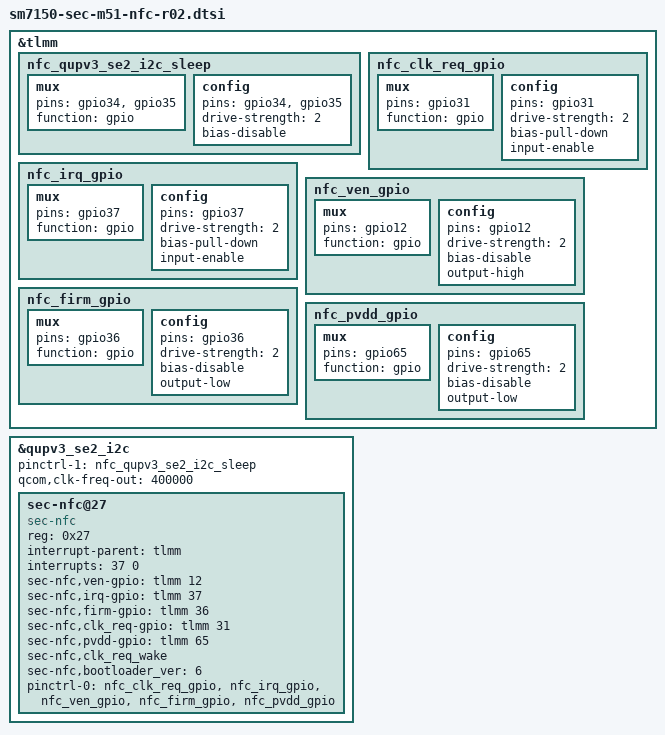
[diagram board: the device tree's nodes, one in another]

/* Copyright (c) 2016-2019, The Linux Foundation. All rights reserved.
 *
 * This program is free software; you can redistribute it and/or modify
 * it under the terms of the GNU General Public License version 2 and
 * only version 2 as published by the Free Software Foundation.
 *
 * This program is distributed in the hope that it will be useful,
 * but WITHOUT ANY WARRANTY; without even the implied warranty of
 * MERCHANTABILITY or FITNESS FOR A PARTICULAR PURPOSE.  See the
 * GNU General Public License for more details.
 */
/*
/ {
	aliases {
		spi2 = &qupv3_se1_spi;
	};
};
*/

&tlmm {
	nfc_qupv3_se2_i2c_sleep: nfc_qupv3_se2_i2c_sleep {
		mux {
			pins = "gpio34", "gpio35";
			function = "gpio";
		};
		config {
			pins = "gpio34", "gpio35";
			drive-strength = <2>;
			bias-disable;
		};
	};

	nfc_clk_req_gpio: nfc_clk_req_gpio {
		mux {
			pins = "gpio31";
			function = "gpio";
		};

		config {
			pins = "gpio31";
			drive-strength = <2>;
			bias-pull-down;
			input-enable;
		};
	};

	nfc_irq_gpio: nfc_irq_gpio {
		mux {
			pins = "gpio37";
			function = "gpio";
		};
		config {
			pins = "gpio37";
			drive-strength = <2>;
			bias-pull-down;
			input-enable;
		};
	};

	nfc_ven_gpio: nfc_ven_gpio {
		mux {
			pins = "gpio12";
			function = "gpio";
		};
		config {
			pins = "gpio12";
			drive-strength = <2>;
			bias-disable;
			output-high;
		};
	};

	nfc_firm_gpio: nfc_firm_gpio {
		mux {
			pins = "gpio36";
			function = "gpio";
		};
		config {
			pins = "gpio36";
			drive-strength = <2>;
			bias-disable;
			output-low;
		};
	};

	nfc_pvdd_gpio: nfc_pvdd_gpio {
		mux {
			pins = "gpio65";
			function = "gpio";
		};
		config {
			pins = "gpio65";
			drive-strength = <2>;
			bias-disable;
			output-low;
		};
	};
};

/* gpio34 and gpio35 are used for nfc i2c */
&qupv3_se2_i2c {
	status = "okay";
	pinctrl-1 = <&nfc_qupv3_se2_i2c_sleep>;
	qcom,clk-freq-out = <400000>;
	sec-nfc@27 {
		compatible = "sec-nfc";
		reg = <0x27>;
		interrupt-parent = <&tlmm>;
		interrupts = <37 0>;

		sec-nfc,ven-gpio = <&tlmm 12 0>;
		sec-nfc,irq-gpio = <&tlmm 37 0>;
		sec-nfc,firm-gpio = <&tlmm 36 0>;
		sec-nfc,clk_req-gpio = <&tlmm 31 0>;
		sec-nfc,pvdd-gpio = <&tlmm 65 0>;
		sec-nfc,clk_req_wake;
		sec-nfc,bootloader_ver = <6>;

		pinctrl-names = "default";
		pinctrl-0 = <&nfc_clk_req_gpio &nfc_irq_gpio &nfc_ven_gpio &nfc_firm_gpio &nfc_pvdd_gpio>;
	};
};
